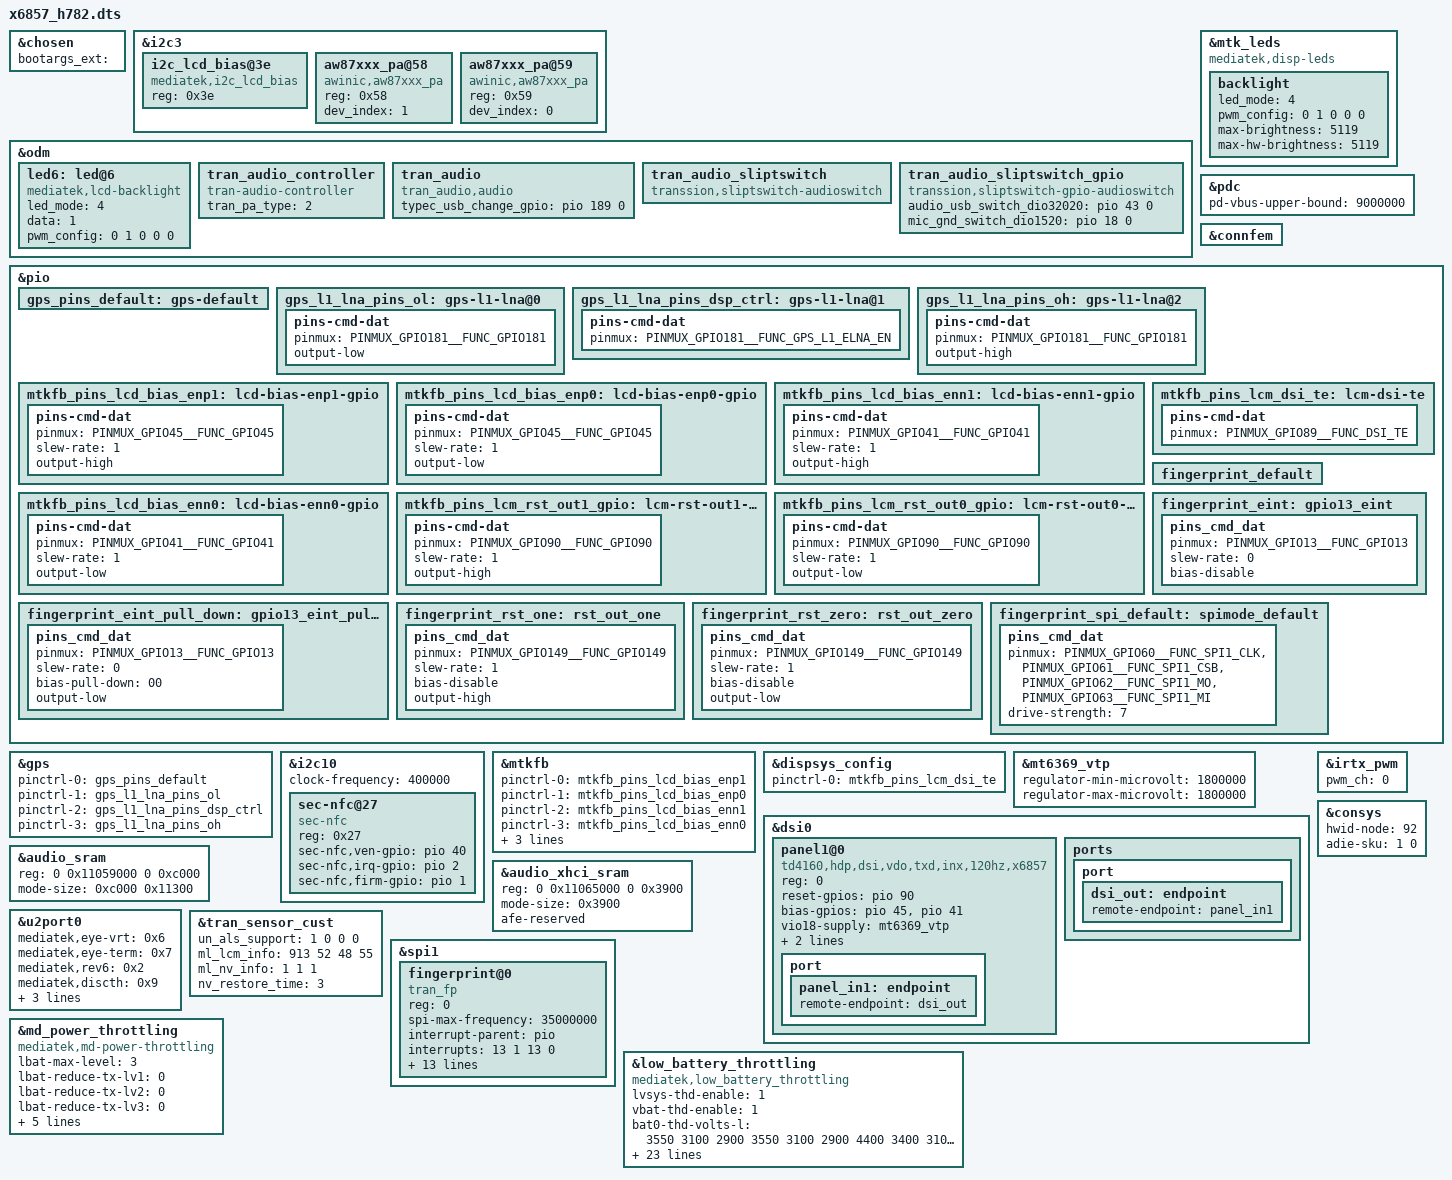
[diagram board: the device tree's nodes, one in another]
// SPDX-License-Identifier: (GPL-2.0 OR MIT)
/*
 * Copyright (C) 2022 MediaTek Inc.
 */
/dts-v1/;
/plugin/;
#include <dt-bindings/interrupt-controller/arm-gic.h>
#include <dt-bindings/interrupt-controller/irq.h>
#include <dt-bindings/phy/phy.h>
#include <dt-bindings/pinctrl/mt6878-pinfunc.h>
#include <dt-bindings/iio/mt635x-auxadc.h>

#if 0
#include <dt-bindings/pinctrl/mt6897-pinfunc.h>
#endif

&chosen {
bootargs_ext = "";
};
&i2c3 {
	i2c_lcd_bias@3e {
		compatible = "mediatek,i2c_lcd_bias";
		reg = <0x3e>;
		status = "okay";
	};
};
&odm {
	led6:led@6 {
		compatible = "mediatek,lcd-backlight";
		led_mode = <4>;
		data = <1>;
		pwm_config = <0 1 0 0 0>;
	};
};
&mtk_leds {
	compatible = "mediatek,disp-leds";
	backlight {
		led_mode = <4>;
		pwm_config = <0 1 0 0 0>;
		max-brightness = <5119>;
		max-hw-brightness = <5119>;
	};
};
&pdc {
	pd-vbus-upper-bound = <9000000>;
};
#if 1
&connfem {
/* Enable epa_elna node to support Wifi & BT ePA/eLNA FEM on customer load */
#if 0
	epa-elna {
		parts = <&wlan7207h &wlan7207c>;
		wifi {
			flags-0 {
				open-loop;
			};
		};
		bt {
			flags-0 {
				/* choose one of: epa-elna/epa/elna/bypass */
				epa-elna;
			};
		};
	};
#endif
};

/* GPS GPIO standardization start */
&pio {
	gps_pins_default: gps-default {
	};
	gps_l1_lna_pins_ol: gps-l1-lna@0 {
		pins-cmd-dat {
			pinmux = <PINMUX_GPIO181__FUNC_GPIO181>;
			output-low;
		};
	};
	gps_l1_lna_pins_dsp_ctrl: gps-l1-lna@1 {
		pins-cmd-dat {
			pinmux = <PINMUX_GPIO181__FUNC_GPS_L1_ELNA_EN>;
		};
	};
	gps_l1_lna_pins_oh: gps-l1-lna@2 {
		pins-cmd-dat {
			pinmux = <PINMUX_GPIO181__FUNC_GPIO181>;
			output-high;
		};
	};
};
&gps {
	pinctrl-names = "default",
		"gps_l1_lna_disable",
		"gps_l1_lna_dsp_ctrl",
		"gps_l1_lna_enable";
	pinctrl-0 = <&gps_pins_default>;
	pinctrl-1 = <&gps_l1_lna_pins_ol>;
	pinctrl-2 = <&gps_l1_lna_pins_dsp_ctrl>;
	pinctrl-3 = <&gps_l1_lna_pins_oh>;
	status = "okay";
};
/* GPS GPIO standardization end */

#endif


&i2c10 {
	clock-frequency = <400000>;
	sec-nfc@27 {
		compatible = "sec-nfc";
		reg = <0x27>;
		sec-nfc,ven-gpio = <&pio 40 0x0>;
		sec-nfc,irq-gpio = <&pio 2 0x0>;
		sec-nfc,firm-gpio = <&pio 1 0x0>;
	};
};

/*
&i2c6 {
	spk: speaker-amp@5c {
		compatible = "richtek,rt5512";
		#address-cells = <1>;
		#size-cells = <0>;
		#sound-dai-cells = <0>;
		reg = <0x5c>;
		status = "okay";
		sound-name-prefix = "Left";
	};
};

&sound {
	mediatek,spk-i2s = <25 24>;
	mediatek,speaker-codec {
		sound-dai = <&spk>;
	};
};
*/

&i2c3 {
	aw87xxx_pa@58 {
		compatible = "awinic,aw87xxx_pa";
		reg = <0x58>;
		dev_index = < 1 >;
		status = "okay";
	};
	aw87xxx_pa@59 {
		compatible = "awinic,aw87xxx_pa";
		reg = <0x59>;
		dev_index = < 0 >;
		status = "okay";
	};
};

&odm {
	tran_audio_controller:tran_audio_controller {
		compatible = "tran-audio-controller";
		tran_pa_type = <2>;
	};
	tran_audio:tran_audio {
		compatible = "tran_audio,audio";
		typec_usb_change_gpio = <&pio 189 0>;
	};
	tran_audio_sliptswitch {
		compatible = "transsion,sliptswitch-audioswitch";
	};
	tran_audio_sliptswitch_gpio {
		compatible = "transsion,sliptswitch-gpio-audioswitch";
		audio_usb_switch_dio32020 = <&pio 43 0>;
		mic_gnd_switch_dio1520 = <&pio 18 0>;
	};
};


&mtkfb {
	pinctrl-names = "lcd_bias_enp1_gpio", "lcd_bias_enp0_gpio",
		"lcd_bias_enn1_gpio", "lcd_bias_enn0_gpio",
		"lcm_rst_out1_gpio", "lcm_rst_out0_gpio",
		"mode_te_te";
	pinctrl-0 = <&mtkfb_pins_lcd_bias_enp1>;
	pinctrl-1 = <&mtkfb_pins_lcd_bias_enp0>;
	pinctrl-2 = <&mtkfb_pins_lcd_bias_enn1>;
	pinctrl-3 = <&mtkfb_pins_lcd_bias_enn0>;
	pinctrl-4 = <&mtkfb_pins_lcm_rst_out1_gpio>;
	pinctrl-5 = <&mtkfb_pins_lcm_rst_out0_gpio>;
	pinctrl-6 = <&mtkfb_pins_lcm_dsi_te>;

	status = "okay";
};

&pio {
	mtkfb_pins_lcd_bias_enp1: lcd-bias-enp1-gpio {
		pins-cmd-dat {
			pinmux = <PINMUX_GPIO45__FUNC_GPIO45>;
			slew-rate = <1>;
			output-high;
		};
	};

	mtkfb_pins_lcd_bias_enp0: lcd-bias-enp0-gpio {
		pins-cmd-dat {
			pinmux = <PINMUX_GPIO45__FUNC_GPIO45>;
			slew-rate = <1>;
			output-low;
		};
	};

	mtkfb_pins_lcd_bias_enn1: lcd-bias-enn1-gpio {
		pins-cmd-dat {
			pinmux = <PINMUX_GPIO41__FUNC_GPIO41>;
			slew-rate = <1>;
			output-high;
		};
	};

	mtkfb_pins_lcd_bias_enn0: lcd-bias-enn0-gpio {
		pins-cmd-dat {
			pinmux = <PINMUX_GPIO41__FUNC_GPIO41>;
			slew-rate = <1>;
			output-low;
		};
	};

	mtkfb_pins_lcm_rst_out1_gpio: lcm-rst-out1-gpio {
		pins-cmd-dat {
			pinmux = <PINMUX_GPIO90__FUNC_GPIO90>;
			slew-rate = <1>;
			output-high;
		};
	};

	mtkfb_pins_lcm_rst_out0_gpio: lcm-rst-out0-gpio {
		pins-cmd-dat {
			pinmux = <PINMUX_GPIO90__FUNC_GPIO90>;
			slew-rate = <1>;
			output-low;
		};
	};
	mtkfb_pins_lcm_dsi_te: lcm-dsi-te {
		pins-cmd-dat {
			pinmux = <PINMUX_GPIO89__FUNC_DSI_TE>;
		};
	};
};

&dispsys_config {
	pinctrl-names = "mode_te_te";
	pinctrl-0 = <&mtkfb_pins_lcm_dsi_te>;
	status = "okay";
};
&mt6369_vtp {
	regulator-min-microvolt = <1800000>;
	regulator-max-microvolt = <1800000>;
};
&dsi0 {
	status = "okay";
	#address-cells = <1>;
	#size-cells = <0>;
	panel1@0 {
		compatible = "td4160,hdp,dsi,vdo,txd,inx,120hz,x6857";
		reg = <0>;
		reset-gpios = <&pio 90 0>;
		bias-gpios = <&pio 45 0>, <&pio 41 0>;
		vio18-supply = <&mt6369_vtp>;
		tp-gpios = <&pio 6 0>;
		pinctrl-names = "default";
		doze_backlight = <3 5 8 31>;
		port {
			panel_in1: endpoint {
				remote-endpoint = <&dsi_out>;
			};
		};
	};
	ports {
		port {
			dsi_out: endpoint {
				remote-endpoint = <&panel_in1>;
			};
		};
	};
};
&audio_sram {
	reg = <0 0x11059000 0 0xc000>;
	mode-size = <0xc000 0x11300>;
};

&audio_xhci_sram {
	reg = <0 0x11065000 0 0x3900>;
	mode-size = <0x3900>;
	afe-reserved;
};

&u2port0 {
	mediatek,eye-vrt = <0x6>;
	mediatek,eye-term = <0x7>;
	mediatek,rev6 = <0x2>;
	mediatek,discth = <0x9>;
	mediatek,eye-vrt-host = <0x7>;
	mediatek,eye-term-host = <0x7>;
	mediatek,rev6-host = <0x2>;
};

&pdc {
	pd-vbus-upper-bound = <9000000>;
};

&irtx_pwm {
	pwm_ch = <0>;
	status = "okay";
};

&tran_sensor_cust {
    /*lcm info for sensor start*/
    /*als sensor support state*/
    un_als_support = <1 0 0 0>;/*ML MSL SL SSL*/
    /*main sensor:ML*/
    ml_lcm_info = <913 52 48 55>;/*offset_x, offset_y, clip_w, clip_h*/
    /*main sub als lcm info:MSL*/
    /*lcm info for sensor end*/
	ml_nv_info = <1 1 1>; /*vendortype:SensorTek,  algotype:Cutout, version:V1_0_0*/
	nv_restore_time = <3>;
};

&spi1 {
    fingerprint@0 {
        compatible = "tran_fp";
        reg = <0>;
        spi-max-frequency = <35000000>;
        interrupt-parent = <&pio>;
        interrupts = <13 1 13 0>;
        debounce = <27 0>;
        irq-gpio = <13>;
        irq-gpio-std = <&pio 13 0x0>;
        reset-gpio = <149>;
        reset-gpio-std = <&pio 149 0x0>;
        vmch-supply = <&mt6369_vfp>;
        history-support;
        pinctrl-names ="tran_fp_default",
            "tran_fp_pin_irq",
            "tran_fp_irq_pull_down",
            "tran_fp_reset_high",
            "tran_fp_reset_low",
            "tran_fp_spi_default";
        pinctrl-0 = <&fingerprint_default>;
        pinctrl-1 = <&fingerprint_eint>;
        pinctrl-2 = <&fingerprint_eint_pull_down>;
        pinctrl-3 = <&fingerprint_rst_one>;
        pinctrl-4 = <&fingerprint_rst_zero>;
        pinctrl-5 = <&fingerprint_spi_default>;
        status = "okay";
    };
};
&pio {
fingerprint_default: fingerprint_default {
                     };
fingerprint_eint: gpio13_eint {
                      pins_cmd_dat {
                          pinmux = <PINMUX_GPIO13__FUNC_GPIO13>;
                          slew-rate = <0>;
                          bias-disable;
                      };
                  };
fingerprint_eint_pull_down: gpio13_eint_pull_down {
                                pins_cmd_dat {
                                    pinmux = <PINMUX_GPIO13__FUNC_GPIO13>;
                                    slew-rate = <0>;
                                    bias-pull-down = <00>;
                                    output-low;
                                };
                            };
fingerprint_rst_one: rst_out_one {
                         pins_cmd_dat {
                             pinmux = <PINMUX_GPIO149__FUNC_GPIO149>;
                             slew-rate = <1>;
                             bias-disable;
                             output-high;
                         };
                     };
fingerprint_rst_zero: rst_out_zero {
                          pins_cmd_dat {
                              pinmux = <PINMUX_GPIO149__FUNC_GPIO149>;
                              slew-rate = <1>;
                              bias-disable;
                              output-low;
                          };
                      };
fingerprint_spi_default: spimode_default {
                             pins_cmd_dat {
                                 pinmux = <PINMUX_GPIO60__FUNC_SPI1_CLK>,
                                        <PINMUX_GPIO61__FUNC_SPI1_CSB>,
                                        <PINMUX_GPIO62__FUNC_SPI1_MO>,
                                        <PINMUX_GPIO63__FUNC_SPI1_MI>;
                                 drive-strength = <7>;
                             };
                         };
};

&consys {
	hwid-node = <92>;
	adie-sku = <1 0>;
};

&md_power_throttling {
	compatible = "mediatek,md-power-throttling";
	lbat-max-level = <3>;
	lbat-reduce-tx-lv1 = <0>;
	lbat-reduce-tx-lv2 = <0>;
	lbat-reduce-tx-lv3 = <0>;
	oc-max-level = <2>;
	oc-reduce-tx-lv1 = <0>;
	oc-reduce-tx-lv2 = <0>;
	soc-max-level = <1>;
	soc-reduce-tx-lv1 = <0>;
};
&low_battery_throttling {
	compatible = "mediatek,low_battery_throttling";
	lvsys-thd-enable = <1>;
	vbat-thd-enable = <1>;
	bat0-thd-volts-l = <
		3550 3100 2900
		3550 3100 2900
		4400 3400 3100
		4400 3400 3100>;
	bat0-thd-volts-h = <
		3600 3550 3100
		3600 3550 3100
		5000 4400 3400
		5000 4400 3400>;
	bat1-thd-volts-l = <
		3550 3100 2900
		3550 3100 2900
		4400 3400 3100
		4400 3400 3100>;
	bat1-thd-volts-h = <
		3600 3550 3100
		3600 3550 3100
		5000 4400 3400
		5000 4400 3400>;
	lvsys-thd-volt-l = <2900>;
	lvsys-thd-volt-h = <3100>;
	temperature-stage-threshold = <25 10 0>;

	bat0-aging-threshold = <1000 2000>;
	bat0-aging-volts-t0 =  <0 0>;
	bat0-aging-volts-t1 =  <0 0>;
	bat0-aging-volts-t2 =  <0 0>;
	bat0-aging-volts-t3 =  <0 0>;
	bat1-aging-threshold = <1000 2000>;
	bat1-aging-volts-t0 =  <0 0>;
	bat1-aging-volts-t1 =  <0 0>;
	bat1-aging-volts-t2 =  <0 0>;
	bat1-aging-volts-t3 =  <0 0>;

	throttle-level = <0 1 2 3>,
					<0 1 2 3>,
					<0 1 2 3>,
					<0 1 2 3>;
	bootmode = <&chosen>;
	gauge = <&mtk_gauge>;
};
#include "mediatek/charge/x6857_h782/mt6375_typec.dtsi"
#include "mediatek/charge/x6857_h782/tc_hl7139a.dtsi"
#include "mediatek/charge/x6857_h782/tran_usb_ctrl.dtsi"
#include "mediatek/charge/x6857_h782/tc_pe50.dtsi"
#include "mediatek/charge/x6857_h782/protocol_ta.dtsi"
#include "mediatek/charge/x6857_h782/tc_charger.dtsi"
#include "mediatek/charge/x6857_h782/tc_charger_lk.dtsi"
#include "mediatek/charge/x6857_h782/authon-overlay.dtsi"
#include "mediatek/charge/x6857_h782/bat_setting/mt6878_battery_prop.dtsi"
#include <x6857_h782/cust.dtsi>
#include "mediatek/tc_led.dtsi"
#include "mediatek/led/x6857_h782/aw210xx_x6857.dtsi"
#include "mediatek/touch/x6857_h782/tran_mt6878_touch_x6857.dtsi"
#include "mediatek/msdc/x6857_h782/cust_mt6878_msdc.dtsi"
#include "mediatek/camera/x6857/cust_mt6878_camera_v4l2.dtsi"
#include "mediatek/cust_k6878_connfem.dtsi"
#include "sensor/tran_mt6881_x6857_h782_sensor.dtsi"
/*End of this file, DO NOT ADD ANYTHING HERE*/

